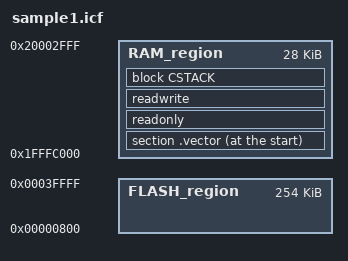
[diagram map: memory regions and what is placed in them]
/**************************************************************************************
*
*   NXP(TM) and the NXP logo are trademarks of NXP
*   All other product or service names are the property of their respective owners.
*   (c) Copyright 2013 - 2016 Freescale Semiconductor Inc.
*   Copyright 2017 NXP
*   All Rights Reserved.
*
*   You can use this example for any purpose on any computer system with the
*   following restrictions:
*
*   1. This example is provided "as is", without warranty.
*
*   2. You don't remove this copyright notice from this example or any direct derivation
*      thereof.
*
*  Description:  IAR linker command file for AUTOSAR OS sample application
*
**************************************************************************************/
/*-Memory Regions-*/
define symbol _FLASH_START_ = 0x00000800;
define symbol _FLASH_END_   = 0x0003FFFF;

define symbol _RAM_START_ = 0x1FFFC000;
define symbol _RAM_END_   = 0x20002FFF;

/*-Sizes-*/
define symbol _STACK_SIZE_ = 0x1000;

define memory mem with size = 4G;

define region FLASH_region = mem:[from _FLASH_START_ to _FLASH_END_];
define region RAM_region   = mem:[from _RAM_START_ to _RAM_END_];

define block CSTACK    with alignment = 8, size = _STACK_SIZE_  { };

initialize by copy { readwrite };

do not initialize  { section .vector };
do not initialize  { section .startup };

place at start of RAM_region  { section .vector };
place in RAM_region   { readonly };

place in RAM_region   { readwrite, block CSTACK };

/* Begin of the RAM area for applications. Do not edit or delete this comment: it is used by the SysGen for IAR */
/* End of the RAM area for applications. Do not edit or delete this comment: it is used by the SysGen for IAR */







